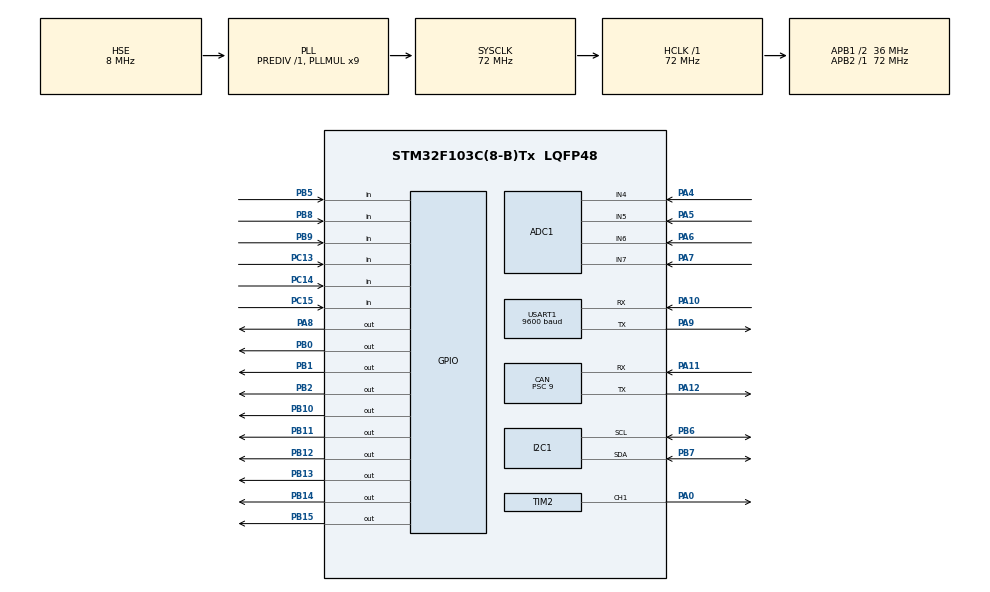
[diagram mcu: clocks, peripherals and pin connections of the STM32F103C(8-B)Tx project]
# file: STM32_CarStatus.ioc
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ADC1.Channel-0\#ChannelRegularConversion=ADC_CHANNEL_4
ADC1.Channel-1\#ChannelRegularConversion=ADC_CHANNEL_5
ADC1.Channel-2\#ChannelRegularConversion=ADC_CHANNEL_6
ADC1.Channel-3\#ChannelRegularConversion=ADC_CHANNEL_7
ADC1.ContinuousConvMode=DISABLE
ADC1.NbrOfConversion=4
ADC1.NbrOfConversionFlag=1
ADC1.Rank-0\#ChannelRegularConversion=1
ADC1.Rank-1\#ChannelRegularConversion=2
ADC1.Rank-2\#ChannelRegularConversion=3
ADC1.Rank-3\#ChannelRegularConversion=4
ADC1.SamplingTime-0\#ChannelRegularConversion=ADC_SAMPLETIME_239CYCLES_5
ADC1.SamplingTime-1\#ChannelRegularConversion=ADC_SAMPLETIME_239CYCLES_5
ADC1.SamplingTime-2\#ChannelRegularConversion=ADC_SAMPLETIME_239CYCLES_5
ADC1.SamplingTime-3\#ChannelRegularConversion=ADC_SAMPLETIME_239CYCLES_5
ADC1.master=1
CAN.BS1=CAN_BS1_3TQ
CAN.BS2=CAN_BS2_4TQ
CAN.CalculateBaudRate=500000
CAN.CalculateTimeBit=2000
CAN.CalculateTimeQuantum=250.0
CAN.Prescaler=9
Dma.ADC1.0.Direction=DMA_PERIPH_TO_MEMORY
Dma.ADC1.0.Instance=DMA1_Channel1
Dma.ADC1.0.MemDataAlignment=DMA_MDATAALIGN_HALFWORD
Dma.ADC1.0.MemInc=DMA_MINC_ENABLE
Dma.ADC1.0.Mode=DMA_CIRCULAR
Dma.ADC1.0.PeriphDataAlignment=DMA_PDATAALIGN_HALFWORD
Dma.ADC1.0.PeriphInc=DMA_PINC_DISABLE
Dma.ADC1.0.Priority=DMA_PRIORITY_LOW
Dma.Request0=ADC1
FREERTOS.Tasks01=defaultTask,0,128,StartDefaultTask,Default,NULL,Dynamic,NULL,NULL;CAN_Handle,2,128,CAN_Handler,Default,NULL,Dynamic,NULL,NULL;Input_Handle,1,128,Input_Handler,Default,NULL,Dynamic,NULL,NULL;Compute_Handle,0,128,Compute_Handler,Default,NULL,Dynamic,NULL,NULL;Control_Handle,0,128,Control_Handler,Default,NULL,Dynamic,NULL,NULL
FREERTOS.configTOTAL_HEAP_SIZE=4096
Mcu.Family=STM32F1
Mcu.Name=STM32F103C(8-B)Tx
Mcu.Package=LQFP48
NVIC.DMA1_Channel1_IRQn=true\:5\:0\:false\:false\:true\:true\:false\:true\:true
NVIC.PriorityGroup=NVIC_PRIORITYGROUP_4
NVIC.TIM3_IRQn=true\:5\:0\:false\:false\:true\:true\:true\:true\:true
NVIC.TIM4_IRQn=true\:15\:0\:false\:false\:true\:false\:false\:true\:true
NVIC.TimeBase=TIM4_IRQn
NVIC.TimeBaseIP=TIM4
PA0-WKUP.Signal=S_TIM2_CH1_ETR
PA10.Mode=Asynchronous
PA10.Signal=USART1_RX
PA11.Mode=CAN_Activate
PA11.Signal=CAN_RX
PA12.Mode=CAN_Activate
PA12.Signal=CAN_TX
PA13.Mode=Serial_Wire
PA13.Signal=SYS_JTMS-SWDIO
PA14.Mode=Serial_Wire
PA14.Signal=SYS_JTCK-SWCLK
PA4.Signal=ADCx_IN4
PA5.Signal=ADCx_IN5
PA6.Signal=ADCx_IN6
PA7.Signal=ADCx_IN7
PA8.Signal=GPIO_Output
PA9.Mode=Asynchronous
PA9.Signal=USART1_TX
PB0.Signal=GPIO_Output
PB1.Signal=GPIO_Output
PB10.Signal=GPIO_Output
PB11.Signal=GPIO_Output
PB12.Signal=GPIO_Output
PB13.Signal=GPIO_Output
PB14.Signal=GPIO_Output
PB15.Signal=GPIO_Output
PB2.Signal=GPIO_Output
PB5.GPIO_PuPd=GPIO_PULLUP
PB5.Signal=GPIO_Input
PB6.Mode=I2C
PB6.Signal=I2C1_SCL
PB7.Mode=I2C
PB7.Signal=I2C1_SDA
PB8.GPIO_PuPd=GPIO_PULLUP
PB8.Signal=GPIO_Input
PB9.GPIO_PuPd=GPIO_PULLUP
PB9.Signal=GPIO_Input
PC13-TAMPER-RTC.GPIO_PuPd=GPIO_PULLUP
PC13-TAMPER-RTC.Signal=GPIO_Input
PC14-OSC32_IN.GPIO_PuPd=GPIO_PULLUP
PC14-OSC32_IN.Signal=GPIO_Input
PC15-OSC32_OUT.GPIO_PuPd=GPIO_PULLUP
PC15-OSC32_OUT.Signal=GPIO_Input
PD0-OSC_IN.Mode=HSE-External-Oscillator
PD0-OSC_IN.Signal=RCC_OSC_IN
PD1-OSC_OUT.Mode=HSE-External-Oscillator
PD1-OSC_OUT.Signal=RCC_OSC_OUT
ProjectManager.HeapSize=0x200
ProjectManager.StackSize=0x400
ProjectManager.TargetToolchain=MDK-ARM V4
RCC.ADCPresc=RCC_ADCPCLK2_DIV6
RCC.AHBFreq_Value=72000000
RCC.APB1CLKDivider=RCC_HCLK_DIV2
RCC.APB1Freq_Value=36000000
RCC.APB1TimFreq_Value=72000000
RCC.APB2Freq_Value=72000000
RCC.APB2TimFreq_Value=72000000
RCC.HCLKFreq_Value=72000000
RCC.PLLMUL=RCC_PLL_MUL9
RCC.PLLSourceVirtual=RCC_PLLSOURCE_HSE
RCC.SYSCLKFreq_VALUE=72000000
RCC.SYSCLKSource=RCC_SYSCLKSOURCE_PLLCLK
RCC.USBFreq_Value=72000000
SH.ADCx_IN4.0=ADC1_IN4,IN4
SH.ADCx_IN5.0=ADC1_IN5,IN5
SH.ADCx_IN6.0=ADC1_IN6,IN6
SH.ADCx_IN7.0=ADC1_IN7,IN7
SH.S_TIM2_CH1_ETR.0=TIM2_CH1,PWM Generation1 CH1
TIM2.AutoReloadPreload=TIM_AUTORELOAD_PRELOAD_ENABLE
TIM2.Channel-PWM\ Generation1\ CH1=TIM_CHANNEL_1
TIM2.Period=19999
TIM2.Prescaler=71
TIM3.Period=999
TIM3.Prescaler=7199
USART1.BaudRate=9600
USART1.VirtualMode=VM_ASYNC
VP_FREERTOS_VS_CMSIS_V1.Mode=CMSIS_V1
VP_SYS_VS_tim4.Mode=TIM4
VP_TIM2_VS_ClockSourceINT.Mode=Internal
VP_TIM3_VS_ClockSourceINT.Mode=Internal
board=custom

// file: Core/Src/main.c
/* USER CODE BEGIN Header */
/**
  ******************************************************************************
  * @file           : main.c
  * @brief          : Main program body
  ******************************************************************************
  * @attention
  *
  * Copyright (c) 2025 STMicroelectronics.
  * All rights reserved.
  *
  * This software is licensed under terms that can be found in the LICENSE file
  * in the root directory of this software component.
  * If no LICENSE file comes with this software, it is provided AS-IS.
  *
  ******************************************************************************
  */
/* USER CODE END Header */
#include "main.h"
#include "cmsis_os.h"

/* USER CODE BEGIN Includes */
#include <string.h>
#include <stdint.h>
#include <stdlib.h>
#include <math.h>
#include "gps.h"
#include "LiquidCrystal_I2C.h"
/* USER CODE END Includes */

/* USER CODE BEGIN PTD */
typedef struct {
    uint8_t engine_status;
    uint8_t light_status;
    uint8_t tire_pressure;
    uint8_t door_status;
    uint8_t seat_belt_status;
    uint8_t battery_level;
    uint8_t speed;
    uint8_t arrived_distance;
    uint8_t total_distance;
    uint8_t arrived_time;
    uint8_t transmission_gear;
    uint8_t speech_enable;
    uint8_t reserved2;
    float gps_lat;
    float gps_lon;
} __attribute__((packed)) VehicleStatus;

/* USER CODE END PTD */

/* USER CODE BEGIN PD */
#define FLASH_USER_START_ADDR    0x0801FC00U  // STM32F103C8: page cuối, 1KB/page

#define VEHICLE_STATUS_CAN_ID 0x023
#define PACKET_HEADER_ID 0x024
#define PACKET_DATA_ID 0x025
#define M_PI 3.14159265358979323846

#define P_Gear 0
#define R_Gear 1
#define N_Gear 2
#define D_Gear 3
/* USER CODE END PD */

ADC_HandleTypeDef hadc1;
DMA_HandleTypeDef hdma_adc1;

CAN_HandleTypeDef hcan;

I2C_HandleTypeDef hi2c1;

TIM_HandleTypeDef htim2;
TIM_HandleTypeDef htim3;

UART_HandleTypeDef huart1;

osThreadId defaultTaskHandle;
osThreadId CAN_HandleHandle;
osThreadId Input_HandleHandle;
osThreadId Compute_HandleHandle;
osThreadId Control_HandleHandle;
/* USER CODE BEGIN PV */
VehicleStatus vehicle_data={0};
uint8_t air_condition_temp = 0;
uint8_t speed_limit = 0;
//--------- CAN message structures------------
CAN_TxHeaderTypeDef TxMsg;
CAN_RxHeaderTypeDef RxHeader;
uint8_t RxData[8];
uint32_t pu32Mailbox;

uint8_t *data_ptr;
uint32_t data_size;
uint8_t frame_count;

volatile uint16_t adc_buffer[4]= {0, 0, 0, 0}; // ADC buffer for joystick and battery

LiquidCrystal_I2C hlcd;

uint8_t can_send_flag = 0;

GPS_t GPS;
int joystick_x = 0;
int joystick_y = 0;

uint32_t distance_metter = 0;
uint32_t arrived_time_s = 0;
int total_distance_readup = 0;

/* USER CODE END PV */

void SystemClock_Config(void);
static void MX_GPIO_Init(void);
static void MX_DMA_Init(void);
static void MX_CAN_Init(void);
static void MX_ADC1_Init(void);
static void MX_I2C1_Init(void);
static void MX_USART1_UART_Init(void);
static void MX_TIM2_Init(void);
static void MX_TIM3_Init(void);
void StartDefaultTask(void const * argument);
void CAN_Handler(void const * argument);
void Input_Handler(void const * argument);
void Compute_Handler(void const * argument);
void Control_Handler(void const * argument);

/* USER CODE BEGIN PFP */
void InitVehicleData(void) {
    vehicle_data.engine_status = 0;
    vehicle_data.light_status = 0;
    vehicle_data.tire_pressure = 0;
    vehicle_data.door_status = 0;
    vehicle_data.seat_belt_status = 0;
    vehicle_data.battery_level = 0;
    vehicle_data.speed = 0;
    vehicle_data.arrived_distance = 0;
    vehicle_data.total_distance = 0;
    vehicle_data.arrived_time = 0;
    vehicle_data.transmission_gear = 0;
    vehicle_data.gps_lat = 0.0f;
    vehicle_data.gps_lon = 0.0f;
}

void SendVehicleStatus(void) {
    data_ptr = (uint8_t*)&vehicle_data;
    data_size = sizeof(VehicleStatus);
    frame_count = (data_size + 6) / 7;  // Changed from (data_size + 7) / 8

    // Send header with frame information
    TxMsg.StdId = PACKET_HEADER_ID;
    TxMsg.DLC = 8;
    uint8_t header_data[8] = {0};
    header_data[0] = frame_count;
    header_data[1] = data_size & 0xFF;
    header_data[2] = (data_size >> 8) & 0xFF;
    header_data[3] = 0x01; // Message type: VehicleStatus

    HAL_CAN_AddTxMessage(&hcan, &TxMsg, header_data, &pu32Mailbox);
    HAL_Delay(10);

    // Send data frame by frame (7 bytes each)
    TxMsg.StdId = PACKET_DATA_ID;
    for (uint8_t i = 0; i < frame_count; i++) {
        uint8_t can_data[8] = {0};
        uint8_t bytes_to_send = (i == frame_count - 1) ?
            (data_size - i * 7) : 7;  // Always 7 bytes except last frame

        can_data[0] = i; // Frame number
        memcpy(&can_data[1], data_ptr + i * 7, bytes_to_send);

        TxMsg.DLC = bytes_to_send + 1;  // +1 for frame number
        HAL_CAN_AddTxMessage(&hcan, &TxMsg, can_data, &pu32Mailbox);
        HAL_Delay(10);
    }
}

void Servo360_Control(uint8_t speed, char direction) {
    uint16_t pulse;
    if (speed == 0) {
        pulse = 1500;
    } else if (direction == 'D') {
        pulse = 1500 + (500 * speed) / 250;
    } else { // 'R'
        pulse = 1500 - (500 * speed) / 250;
    }
    __HAL_TIM_SET_COMPARE(&htim2, TIM_CHANNEL_1, pulse);
}

void Flash_Write(uint8_t value)
{
    HAL_FLASH_Unlock();
    FLASH_EraseInitTypeDef eraseInitStruct;
    uint32_t pageError = 0;
    eraseInitStruct.TypeErase = FLASH_TYPEERASE_PAGES;
    eraseInitStruct.PageAddress = FLASH_USER_START_ADDR;
    eraseInitStruct.NbPages = 1;
    HAL_FLASHEx_Erase(&eraseInitStruct, &pageError);

    // Ghi 1 word, chỉ dùng 1 byte, 3 byte còn lại = 0xFF
    uint32_t data = (uint32_t)value ; // Nếu thích, có thể để các bit cao = 0xFF
    HAL_FLASH_Program(FLASH_TYPEPROGRAM_WORD, FLASH_USER_START_ADDR, data);

    HAL_FLASH_Lock();
}

uint8_t Flash_Read(void)
{
    uint32_t data = *(uint32_t*)FLASH_USER_START_ADDR;
    return (uint8_t)(data );
}
/* USER CODE END PFP */

/* USER CODE BEGIN 0 */

void HAL_UART_RxCpltCallback(UART_HandleTypeDef *huart)
{
	if(huart == &huart1)
  {
    GPS_UART_CallBack(&huart1,&GPS);
  }
}

#if (configSUPPORT_STATIC_ALLOCATION == 1)

#define TIMER_TASK_STACK_DEPTH  (128 )

static StaticTask_t xTimerTaskTCB;
static StackType_t xTimerStack[TIMER_TASK_STACK_DEPTH];

void vApplicationGetTimerTaskMemory( StaticTask_t **ppxTimerTaskTCBBuffer,
                                     StackType_t **ppxTimerTaskStackBuffer,
                                     uint32_t *pulTimerTaskStackSize )
{
    *ppxTimerTaskTCBBuffer = &xTimerTaskTCB;
    *ppxTimerTaskStackBuffer = xTimerStack;
    *pulTimerTaskStackSize = TIMER_TASK_STACK_DEPTH;
}

#endif

/* USER CODE END 0 */

int main(void)
{

  /* MCU Configuration--------------------------------------------------------*/

  /* Reset of all peripherals, Initializes the Flash interface and the Systick. */
  HAL_Init();

  /* Configure the system clock */
  SystemClock_Config();

  /* Initialize all configured peripherals */
  MX_GPIO_Init();
  MX_DMA_Init();
  MX_CAN_Init();
  MX_ADC1_Init();
  MX_I2C1_Init();
  MX_USART1_UART_Init();
  MX_TIM2_Init();
  MX_TIM3_Init();

  /* Create the thread(s) */
  /* definition and creation of defaultTask */
  osThreadDef(defaultTask, StartDefaultTask, osPriorityNormal, 0, 128);
  defaultTaskHandle = osThreadCreate(osThread(defaultTask), NULL);

  /* definition and creation of CAN_Handle */
  osThreadDef(CAN_Handle, CAN_Handler, osPriorityHigh, 0, 128);
  CAN_HandleHandle = osThreadCreate(osThread(CAN_Handle), NULL);

  /* definition and creation of Input_Handle */
  osThreadDef(Input_Handle, Input_Handler, osPriorityAboveNormal, 0, 128);
  Input_HandleHandle = osThreadCreate(osThread(Input_Handle), NULL);

  /* definition and creation of Compute_Handle */
  osThreadDef(Compute_Handle, Compute_Handler, osPriorityNormal, 0, 128);
  Compute_HandleHandle = osThreadCreate(osThread(Compute_Handle), NULL);

  /* definition and creation of Control_Handle */
  osThreadDef(Control_Handle, Control_Handler, osPriorityNormal, 0, 128);
  Control_HandleHandle = osThreadCreate(osThread(Control_Handle), NULL);

  /* Start scheduler */
  osKernelStart();

  /* We should never get here as control is now taken by the scheduler */
  /* Infinite loop */
  while (1)
  {

  }
}

void SystemClock_Config(void)
{
  RCC_OscInitTypeDef RCC_OscInitStruct = {0};
  RCC_ClkInitTypeDef RCC_ClkInitStruct = {0};
  RCC_PeriphCLKInitTypeDef PeriphClkInit = {0};

  /** Initializes the RCC Oscillators according to the specified parameters
  * in the RCC_OscInitTypeDef structure.
  */
  RCC_OscInitStruct.OscillatorType = RCC_OSCILLATORTYPE_HSE;
  RCC_OscInitStruct.HSEState = RCC_HSE_ON;
  RCC_OscInitStruct.HSEPredivValue = RCC_HSE_PREDIV_DIV1;
  RCC_OscInitStruct.HSIState = RCC_HSI_ON;
  RCC_OscInitStruct.PLL.PLLState = RCC_PLL_ON;
  RCC_OscInitStruct.PLL.PLLSource = RCC_PLLSOURCE_HSE;
  RCC_OscInitStruct.PLL.PLLMUL = RCC_PLL_MUL9;
  if (HAL_RCC_OscConfig(&RCC_OscInitStruct) != HAL_OK)
  {
    Error_Handler();
  }

  /** Initializes the CPU, AHB and APB buses clocks
  */
  RCC_ClkInitStruct.ClockType = RCC_CLOCKTYPE_HCLK|RCC_CLOCKTYPE_SYSCLK
                              |RCC_CLOCKTYPE_PCLK1|RCC_CLOCKTYPE_PCLK2;
  RCC_ClkInitStruct.SYSCLKSource = RCC_SYSCLKSOURCE_PLLCLK;
  RCC_ClkInitStruct.AHBCLKDivider = RCC_SYSCLK_DIV1;
  RCC_ClkInitStruct.APB1CLKDivider = RCC_HCLK_DIV2;
  RCC_ClkInitStruct.APB2CLKDivider = RCC_HCLK_DIV1;

  if (HAL_RCC_ClockConfig(&RCC_ClkInitStruct, FLASH_LATENCY_2) != HAL_OK)
  {
    Error_Handler();
  }
  PeriphClkInit.PeriphClockSelection = RCC_PERIPHCLK_ADC;
  PeriphClkInit.AdcClockSelection = RCC_ADCPCLK2_DIV6;
  if (HAL_RCCEx_PeriphCLKConfig(&PeriphClkInit) != HAL_OK)
  {
    Error_Handler();
  }
}

static void MX_ADC1_Init(void)
{

  ADC_ChannelConfTypeDef sConfig = {0};

  /** Common config
  */
  hadc1.Instance = ADC1;
  hadc1.Init.ScanConvMode = ADC_SCAN_ENABLE;
  hadc1.Init.ContinuousConvMode = ENABLE;
  hadc1.Init.DiscontinuousConvMode = DISABLE;
  hadc1.Init.ExternalTrigConv = ADC_SOFTWARE_START;
  hadc1.Init.DataAlign = ADC_DATAALIGN_RIGHT;
  hadc1.Init.NbrOfConversion = 4;
  if (HAL_ADC_Init(&hadc1) != HAL_OK)
  {
    Error_Handler();
  }

  /** Configure Regular Channel
  */
  sConfig.Channel = ADC_CHANNEL_4;
  sConfig.Rank = ADC_REGULAR_RANK_1;
  sConfig.SamplingTime = ADC_SAMPLETIME_239CYCLES_5;
  if (HAL_ADC_ConfigChannel(&hadc1, &sConfig) != HAL_OK)
  {
    Error_Handler();
  }

  /** Configure Regular Channel
  */
  sConfig.Channel = ADC_CHANNEL_5;
  sConfig.Rank = ADC_REGULAR_RANK_2;
  if (HAL_ADC_ConfigChannel(&hadc1, &sConfig) != HAL_OK)
  {
    Error_Handler();
  }

  /** Configure Regular Channel
  */
  sConfig.Channel = ADC_CHANNEL_6;
  sConfig.Rank = ADC_REGULAR_RANK_3;
  if (HAL_ADC_ConfigChannel(&hadc1, &sConfig) != HAL_OK)
  {
    Error_Handler();
  }

  /** Configure Regular Channel
  */
  sConfig.Channel = ADC_CHANNEL_7;
  sConfig.Rank = ADC_REGULAR_RANK_4;
  if (HAL_ADC_ConfigChannel(&hadc1, &sConfig) != HAL_OK)
  {
    Error_Handler();
  }

}

static void MX_CAN_Init(void)
{

  hcan.Instance = CAN1;
  hcan.Init.Prescaler = 9;
  hcan.Init.Mode = CAN_MODE_NORMAL;
  hcan.Init.SyncJumpWidth = CAN_SJW_1TQ;
  hcan.Init.TimeSeg1 = CAN_BS1_3TQ;
  hcan.Init.TimeSeg2 = CAN_BS2_4TQ;
  hcan.Init.TimeTriggeredMode = DISABLE;
  hcan.Init.AutoBusOff = DISABLE;
  hcan.Init.AutoWakeUp = DISABLE;
  hcan.Init.AutoRetransmission = DISABLE;
  hcan.Init.ReceiveFifoLocked = DISABLE;
  hcan.Init.TransmitFifoPriority = DISABLE;
  if (HAL_CAN_Init(&hcan) != HAL_OK)
  {
    Error_Handler();
  }

}

static void MX_I2C1_Init(void)
{

  hi2c1.Instance = I2C1;
  hi2c1.Init.ClockSpeed = 100000;
  hi2c1.Init.DutyCycle = I2C_DUTYCYCLE_2;
  hi2c1.Init.OwnAddress1 = 0;
  hi2c1.Init.AddressingMode = I2C_ADDRESSINGMODE_7BIT;
  hi2c1.Init.DualAddressMode = I2C_DUALADDRESS_DISABLE;
  hi2c1.Init.OwnAddress2 = 0;
  hi2c1.Init.GeneralCallMode = I2C_GENERALCALL_DISABLE;
  hi2c1.Init.NoStretchMode = I2C_NOSTRETCH_DISABLE;
  if (HAL_I2C_Init(&hi2c1) != HAL_OK)
  {
    Error_Handler();
  }

}

static void MX_TIM2_Init(void)
{

  TIM_ClockConfigTypeDef sClockSourceConfig = {0};
  TIM_MasterConfigTypeDef sMasterConfig = {0};
  TIM_OC_InitTypeDef sConfigOC = {0};

  htim2.Instance = TIM2;
  htim2.Init.Prescaler = 71;
  htim2.Init.CounterMode = TIM_COUNTERMODE_UP;
  htim2.Init.Period = 19999;
  htim2.Init.ClockDivision = TIM_CLOCKDIVISION_DIV1;
  htim2.Init.AutoReloadPreload = TIM_AUTORELOAD_PRELOAD_ENABLE;
  if (HAL_TIM_Base_Init(&htim2) != HAL_OK)
  {
    Error_Handler();
  }
  sClockSourceConfig.ClockSource = TIM_CLOCKSOURCE_INTERNAL;
  if (HAL_TIM_ConfigClockSource(&htim2, &sClockSourceConfig) != HAL_OK)
  {
    Error_Handler();
  }
  if (HAL_TIM_PWM_Init(&htim2) != HAL_OK)
  {
    Error_Handler();
  }
  sMasterConfig.MasterOutputTrigger = TIM_TRGO_RESET;
  sMasterConfig.MasterSlaveMode = TIM_MASTERSLAVEMODE_DISABLE;
  if (HAL_TIMEx_MasterConfigSynchronization(&htim2, &sMasterConfig) != HAL_OK)
  {
    Error_Handler();
  }
  sConfigOC.OCMode = TIM_OCMODE_PWM1;
  sConfigOC.Pulse = 0;
  sConfigOC.OCPolarity = TIM_OCPOLARITY_HIGH;
  sConfigOC.OCFastMode = TIM_OCFAST_DISABLE;
  if (HAL_TIM_PWM_ConfigChannel(&htim2, &sConfigOC, TIM_CHANNEL_1) != HAL_OK)
  {
    Error_Handler();
  }
  HAL_TIM_MspPostInit(&htim2);

}

static void MX_TIM3_Init(void)
{

  TIM_ClockConfigTypeDef sClockSourceConfig = {0};
  TIM_MasterConfigTypeDef sMasterConfig = {0};

  htim3.Instance = TIM3;
  htim3.Init.Prescaler = 7199;
  htim3.Init.CounterMode = TIM_COUNTERMODE_UP;
  htim3.Init.Period = 9999;
  htim3.Init.ClockDivision = TIM_CLOCKDIVISION_DIV1;
  htim3.Init.AutoReloadPreload = TIM_AUTORELOAD_PRELOAD_DISABLE;
  if (HAL_TIM_Base_Init(&htim3) != HAL_OK)
  {
    Error_Handler();
  }
  sClockSourceConfig.ClockSource = TIM_CLOCKSOURCE_INTERNAL;
  if (HAL_TIM_ConfigClockSource(&htim3, &sClockSourceConfig) != HAL_OK)
  {
    Error_Handler();
  }
  sMasterConfig.MasterOutputTrigger = TIM_TRGO_RESET;
  sMasterConfig.MasterSlaveMode = TIM_MASTERSLAVEMODE_DISABLE;
  if (HAL_TIMEx_MasterConfigSynchronization(&htim3, &sMasterConfig) != HAL_OK)
  {
    Error_Handler();
  }

}

static void MX_USART1_UART_Init(void)
{

  huart1.Instance = USART1;
  huart1.Init.BaudRate = 9600;
  huart1.Init.WordLength = UART_WORDLENGTH_8B;
  huart1.Init.StopBits = UART_STOPBITS_1;
  huart1.Init.Parity = UART_PARITY_NONE;
  huart1.Init.Mode = UART_MODE_TX_RX;
  huart1.Init.HwFlowCtl = UART_HWCONTROL_NONE;
  huart1.Init.OverSampling = UART_OVERSAMPLING_16;
  if (HAL_UART_Init(&huart1) != HAL_OK)
  {
    Error_Handler();
  }

}

static void MX_DMA_Init(void)
{

  /* DMA controller clock enable */
  __HAL_RCC_DMA1_CLK_ENABLE();

  /* DMA interrupt init */
  /* DMA1_Channel1_IRQn interrupt configuration */
  HAL_NVIC_SetPriority(DMA1_Channel1_IRQn, 5, 0);
  HAL_NVIC_EnableIRQ(DMA1_Channel1_IRQn);

}

static void MX_GPIO_Init(void)
{
  GPIO_InitTypeDef GPIO_InitStruct = {0};

  /* GPIO Ports Clock Enable */
  __HAL_RCC_GPIOC_CLK_ENABLE();
  __HAL_RCC_GPIOD_CLK_ENABLE();
  __HAL_RCC_GPIOA_CLK_ENABLE();
  __HAL_RCC_GPIOB_CLK_ENABLE();

  /*Configure GPIO pin Output Level */
  HAL_GPIO_WritePin(GPIOB, GPIO_PIN_0|GPIO_PIN_1|GPIO_PIN_4|GPIO_PIN_10
                          |GPIO_PIN_11|GPIO_PIN_12|GPIO_PIN_13|GPIO_PIN_14
                          |GPIO_PIN_15, GPIO_PIN_RESET);

  /*Configure GPIO pin Output Level */
  HAL_GPIO_WritePin(GPIOA, GPIO_PIN_8, GPIO_PIN_RESET);

  /*Configure GPIO pins : PC13 PC14 PC15 */
  GPIO_InitStruct.Pin = GPIO_PIN_13|GPIO_PIN_14|GPIO_PIN_15;
  GPIO_InitStruct.Mode = GPIO_MODE_INPUT;
  GPIO_InitStruct.Pull = GPIO_PULLUP;
  HAL_GPIO_Init(GPIOC, &GPIO_InitStruct);

  /*Configure GPIO pins : PB0 PB1 PB2 PB10
                           PB11 PB12 PB13 PB14
                           PB15 */
  GPIO_InitStruct.Pin = GPIO_PIN_0|GPIO_PIN_1|GPIO_PIN_4|GPIO_PIN_10
                          |GPIO_PIN_11|GPIO_PIN_12|GPIO_PIN_13|GPIO_PIN_14
                          |GPIO_PIN_15;
  GPIO_InitStruct.Mode = GPIO_MODE_OUTPUT_PP;
  GPIO_InitStruct.Pull = GPIO_NOPULL;
  GPIO_InitStruct.Speed = GPIO_SPEED_FREQ_LOW;
  HAL_GPIO_Init(GPIOB, &GPIO_InitStruct);

  /*Configure GPIO pin : PA8 */
  GPIO_InitStruct.Pin = GPIO_PIN_8;
  GPIO_InitStruct.Mode = GPIO_MODE_OUTPUT_PP;
  GPIO_InitStruct.Pull = GPIO_NOPULL;
  GPIO_InitStruct.Speed = GPIO_SPEED_FREQ_LOW;
  HAL_GPIO_Init(GPIOA, &GPIO_InitStruct);

  /*Configure GPIO pins : PB5 PB8 PB9 */
  GPIO_InitStruct.Pin = GPIO_PIN_5|GPIO_PIN_8|GPIO_PIN_9;
  GPIO_InitStruct.Mode = GPIO_MODE_INPUT;
  GPIO_InitStruct.Pull = GPIO_PULLUP;
  HAL_GPIO_Init(GPIOB, &GPIO_InitStruct);

}

void StartDefaultTask(void const * argument)
{
  for(;;)
  {
    osDelay(1);
  }
}

void CAN_Handler(void const * argument)
{
  /* USER CODE BEGIN CAN_Handler */
  TxMsg.DLC = 8;
  TxMsg.IDE = CAN_ID_STD;
  TxMsg.RTR = CAN_RTR_DATA;
  TxMsg.TransmitGlobalTime = DISABLE;

  // Cấu hình CAN filter để nhận message air condition
  CAN_FilterTypeDef canfilterconfig;

  // Gộp filter cho các ID 0x024, 0x025, 0x030 bằng cách dùng ID mask
  canfilterconfig.FilterActivation = CAN_FILTER_ENABLE;
  canfilterconfig.FilterBank = 0;
  canfilterconfig.FilterFIFOAssignment = CAN_RX_FIFO0;
  canfilterconfig.FilterIdHigh = 0x000 << 5;
  canfilterconfig.FilterIdLow = 0x0000;
  canfilterconfig.FilterMaskIdHigh = 0x000 << 5;
  canfilterconfig.FilterMaskIdLow = 0x0000;
  canfilterconfig.FilterMode = CAN_FILTERMODE_IDMASK;
  canfilterconfig.FilterScale = CAN_FILTERSCALE_32BIT;

  HAL_CAN_ConfigFilter(&hcan, &canfilterconfig);

  HAL_CAN_Start(&hcan); // start CAN
  /* Infinite loop */
  for(;;)
  {
    // Send vehicle status periodically
    if(can_send_flag) {
        can_send_flag = 0; // Reset flag
        SendVehicleStatus();
    }
    // Wait for CAN messages
    if (HAL_CAN_GetRxFifoFillLevel(&hcan, CAN_RX_FIFO0) > 0) {
        CAN_RxHeaderTypeDef RxHeader;
        uint8_t RxData[8];
        if (HAL_CAN_GetRxMessage(&hcan, CAN_RX_FIFO0, &RxHeader, RxData) == HAL_OK) {
            if (RxHeader.StdId == 0x030 && RxHeader.DLC >= 1) {
                vehicle_data.engine_status = RxData[2]; // Update engine status
                vehicle_data.light_status = RxData[3]; // Update engine status
                vehicle_data.door_status = RxData[4]; // Update door status
                air_condition_temp = RxData[0];
                speed_limit = RxData[1];
            }
        }
    }
    osDelay(50); // Delay to avoid busy loop
  }
  /* USER CODE END CAN_Handler */
}

void Input_Handler(void const * argument)
{
  /* USER CODE BEGIN Input_Handler */
  InitVehicleData();
  HAL_ADCEx_Calibration_Start(&hadc1);
  HAL_ADC_Start_DMA(&hadc1, (uint32_t*)adc_buffer, 4);
  //UART2 receive callback
  GPS_Init(&huart1);

  uint8_t engine_button_last=0, engine_button_cur=0;
  uint8_t light_button_last=0, light_button_cur=0;
  uint8_t tire_button_last=0, tire_button_cur=0;
  uint8_t door_button_last=0, door_button_cur=0;
  uint8_t seatbelt_button_last=0, seatbelt_button_cur=0;

  /* Infinite loop */
  for(;;)
  {
    // Update GPS data
    if(GPS.dec_latitude != 0.0f && GPS.dec_longitude != 0.0f) {
      vehicle_data.gps_lat = GPS.dec_latitude;
      vehicle_data.gps_lon = GPS.dec_longitude;
    }
    // Read engine status
    engine_button_cur = !HAL_GPIO_ReadPin(GPIOC, GPIO_PIN_15);
    if(engine_button_cur && !engine_button_last)
    {
      can_send_flag=1;
      vehicle_data.engine_status = (vehicle_data.engine_status + 1) % 2; // Toggle engine status
      if(vehicle_data.engine_status == 0)
      {
        Flash_Write(vehicle_data.total_distance);
        HAL_TIM_Base_Stop_IT(&htim3);
      }
      else
      {
        total_distance_readup = Flash_Read();
        HAL_TIM_Base_Start_IT(&htim3);
      }
    }
    engine_button_last = engine_button_cur;

    // Read door status
    door_button_cur = !HAL_GPIO_ReadPin(GPIOB, GPIO_PIN_9);
    if(door_button_cur && !door_button_last)
    {
      can_send_flag=1;
      vehicle_data.door_status = (vehicle_data.door_status + 1) % 2; // Toggle door status
    }
    door_button_last = door_button_cur;

    // Read battery level
    if(abs(vehicle_data.battery_level  - adc_buffer[1] * 100 / 4095) > 2) {
          can_send_flag = 1; // Set flag to send vehicle status
          vehicle_data.battery_level = adc_buffer[1] * 100 / 4095; // Assuming 0-4095 ADC range
      }

    if(vehicle_data.engine_status == 1) {
      // Read light status
      light_button_cur = !HAL_GPIO_ReadPin(GPIOC, GPIO_PIN_14);
      if(light_button_cur && !light_button_last)
      {
        can_send_flag=1;
        vehicle_data.light_status = (vehicle_data.light_status + 1) % 4; // Cycle through light status
      }
      light_button_last = light_button_cur;

      // Read tire pressure
      tire_button_cur = !HAL_GPIO_ReadPin(GPIOC, GPIO_PIN_13);
      if(tire_button_cur && !tire_button_last)
      {
        can_send_flag=1;
        vehicle_data.tire_pressure = (vehicle_data.tire_pressure + 1) % 2; // Toggle tire pressure status
      }
      tire_button_last = tire_button_cur;

      //Read set belt status
      seatbelt_button_cur = !HAL_GPIO_ReadPin(GPIOB, GPIO_PIN_8);
      if(seatbelt_button_cur && !seatbelt_button_last)
      {
        can_send_flag=1;
        vehicle_data.seat_belt_status = (vehicle_data.seat_belt_status + 1) % 2; // Toggle seat belt status
      }
      seatbelt_button_last = seatbelt_button_cur;

      //Read enable speech
      vehicle_data.speech_enable = !HAL_GPIO_ReadPin(GPIOB, GPIO_PIN_5);

      // Read ADC values
      if(vehicle_data.transmission_gear == D_Gear || vehicle_data.transmission_gear == R_Gear) {
          if(abs(adc_buffer[0] * 250 / 4095 - vehicle_data.speed) > 2) {
              can_send_flag = 1; // Set flag to send vehicle status
              vehicle_data.speed = adc_buffer[0] * 250 / 4095; // Assuming 0-4095 ADC range
          }
      } else {
          vehicle_data.speed = 0; // Reset speed if not in D or R gear
      }

      if(abs(joystick_x - adc_buffer[2])>200 || abs(joystick_y - adc_buffer[3])>200) {
          can_send_flag = 1; // Set flag to send vehicle status

          joystick_x = adc_buffer[2]; // Joystick X-axis
          joystick_y = adc_buffer[3]; // Joystick Y-axis

          float dx = (float)joystick_x - 3150;
          float dy = (float)joystick_y - 3150;

          if( !(dx < 100 && dx > -100 && dy <100 && dy > -100))
          {
              // Tính góc (angle) theo đơn vị độ
            float angle = atan2f(dy, dx) * 180.0f / M_PI;

            // Chuẩn hóa v�? [0, 360) nếu cần
            if (angle < 0)
                angle += 360.0f;

            if (angle >= 45 && angle < 135) {
                vehicle_data.transmission_gear = D_Gear;
            } else if (angle >= 135 && angle < 225) {
                vehicle_data.transmission_gear = P_Gear;
            } else if (angle >= 225 && angle < 315) {
                vehicle_data.transmission_gear = R_Gear;
            } else { // từ 315–360 hoặc 0–45
                vehicle_data.transmission_gear = N_Gear;
            }
          }

      }
    }
    else
    {
      vehicle_data.light_status = 0;
      vehicle_data.speed = 0;
      vehicle_data.transmission_gear = P_Gear;
    }
    osDelay(20);
  }
  /* USER CODE END Input_Handler */
}

void Compute_Handler(void const * argument)
{
  /* USER CODE BEGIN Compute_Handler */
  /* Infinite loop */
  for(;;)
  {
    vehicle_data.arrived_time = arrived_time_s/ 60; // Convert seconds to minutes
    vehicle_data.arrived_distance = distance_metter/1000; // Convert meters to kilometers
    vehicle_data.total_distance = total_distance_readup + vehicle_data.arrived_distance;
    osDelay(100);
  }
  /* USER CODE END Compute_Handler */
}

void Control_Handler(void const * argument)
{
  /* USER CODE BEGIN Control_Handler */
  HAL_TIM_PWM_Start(&htim2, TIM_CHANNEL_1);
  lcd_init(&hlcd, &hi2c1, LCD_ADDR_DEFAULT);// Khởi tạo LCD với địa chỉ mặc định
  /* Infinite loop */
  for(;;)
  {
    // Display door status on LEDs
    if(vehicle_data.door_status == 1) {
      HAL_GPIO_WritePin(GPIOB, GPIO_PIN_10, GPIO_PIN_SET); // All doors closed
      HAL_GPIO_WritePin(GPIOB, GPIO_PIN_4, GPIO_PIN_RESET);
    } else {
      HAL_GPIO_WritePin(GPIOB, GPIO_PIN_10, GPIO_PIN_RESET); // At least one door open
      HAL_GPIO_WritePin(GPIOB, GPIO_PIN_4, GPIO_PIN_SET);
    }

    if(vehicle_data.engine_status==1)
    {
      HAL_GPIO_WritePin(GPIOA, GPIO_PIN_8, GPIO_PIN_SET); // Turn on engine
      // Display light status on LEDs
      switch (vehicle_data.light_status)
      {
        case 0:
          HAL_GPIO_WritePin(GPIOB, GPIO_PIN_15, GPIO_PIN_RESET);
          HAL_GPIO_WritePin(GPIOB, GPIO_PIN_14, GPIO_PIN_RESET);
          HAL_GPIO_WritePin(GPIOB, GPIO_PIN_13, GPIO_PIN_RESET);
          break;
        case 1:
          HAL_GPIO_WritePin(GPIOB, GPIO_PIN_15, GPIO_PIN_SET);
          HAL_GPIO_WritePin(GPIOB, GPIO_PIN_14, GPIO_PIN_RESET);
          HAL_GPIO_WritePin(GPIOB, GPIO_PIN_13, GPIO_PIN_RESET);
          break;
        case 2:
          HAL_GPIO_WritePin(GPIOB, GPIO_PIN_15, GPIO_PIN_RESET);
          HAL_GPIO_WritePin(GPIOB, GPIO_PIN_14, GPIO_PIN_SET);
          HAL_GPIO_WritePin(GPIOB, GPIO_PIN_13, GPIO_PIN_RESET);
          break;
        case 3:
          HAL_GPIO_WritePin(GPIOB, GPIO_PIN_15, GPIO_PIN_RESET);
          HAL_GPIO_WritePin(GPIOB, GPIO_PIN_14, GPIO_PIN_RESET);
          HAL_GPIO_WritePin(GPIOB, GPIO_PIN_13, GPIO_PIN_SET);
          break;
        default:
          break;
      }
      //Display tire pressure on LEDs
      if(vehicle_data.tire_pressure == 1) {
        HAL_GPIO_WritePin(GPIOB, GPIO_PIN_12, GPIO_PIN_SET); // Tire pressure enough
        HAL_GPIO_WritePin(GPIOB, GPIO_PIN_11, GPIO_PIN_RESET);
      } else {
        HAL_GPIO_WritePin(GPIOB, GPIO_PIN_12, GPIO_PIN_RESET); // Tire pressure low
        HAL_GPIO_WritePin(GPIOB, GPIO_PIN_11, GPIO_PIN_SET);
      }

      // Display seat belt status on LEDs
      if(vehicle_data.seat_belt_status == 1) {
        HAL_GPIO_WritePin(GPIOB, GPIO_PIN_1, GPIO_PIN_SET); // Seat belt fastened
        HAL_GPIO_WritePin(GPIOB, GPIO_PIN_0, GPIO_PIN_RESET);
      } else {
        HAL_GPIO_WritePin(GPIOB, GPIO_PIN_1, GPIO_PIN_RESET); // Seat belt unfastened
        HAL_GPIO_WritePin(GPIOB, GPIO_PIN_0, GPIO_PIN_SET);
      }

      //Display speed
      if(vehicle_data.transmission_gear == D_Gear) {
        Servo360_Control(vehicle_data.speed, 'D'); // Forward
      }
      else if(vehicle_data.transmission_gear == R_Gear)
      {
        Servo360_Control(vehicle_data.speed, 'R');
      }
      else
      {
        Servo360_Control(0, 'N'); // Neutral or Park
      }
      //Display lCD
      lcd_backlight_on(&hlcd);
      lcd_set_cursor(&hlcd, 0,0);
      lcd_printf(&hlcd, "SpeedLimit: %d", speed_limit);
      lcd_set_cursor(&hlcd, 1,0);
      lcd_printf(&hlcd, "AirTemp: %d", air_condition_temp);
    }
    else
    {
        HAL_GPIO_WritePin(GPIOA, GPIO_PIN_8, GPIO_PIN_RESET);
        HAL_GPIO_WritePin(GPIOB, GPIO_PIN_15, GPIO_PIN_RESET);
        HAL_GPIO_WritePin(GPIOB, GPIO_PIN_14, GPIO_PIN_RESET);
        HAL_GPIO_WritePin(GPIOB, GPIO_PIN_13, GPIO_PIN_RESET);
        HAL_GPIO_WritePin(GPIOB, GPIO_PIN_12, GPIO_PIN_RESET);
        HAL_GPIO_WritePin(GPIOB, GPIO_PIN_11, GPIO_PIN_RESET);
        HAL_GPIO_WritePin(GPIOB, GPIO_PIN_1, GPIO_PIN_RESET);
        HAL_GPIO_WritePin(GPIOB, GPIO_PIN_0, GPIO_PIN_RESET);
        vehicle_data.speed = 0; // Reset speed when engine is off
        Servo360_Control(0, 'R');
        lcd_backlight_off(&hlcd);
    }
    osDelay(20);
  }
  /* USER CODE END Control_Handler */
}

void HAL_TIM_PeriodElapsedCallback(TIM_HandleTypeDef *htim)
{
  /* USER CODE BEGIN Callback 0 */
  if (htim->Instance == TIM3) {
    arrived_time_s +=1;
    distance_metter += round( ((float)vehicle_data.speed / 3.6f) ); // Convert speed from km/h to m/s);
    if(arrived_time_s % 2 ==0)
    {
      can_send_flag = 1; // Set flag to send data
    }
  }
  /* USER CODE END Callback 0 */
  if (htim->Instance == TIM4) {
    HAL_IncTick();
  }
}

void Error_Handler(void)
{
  __disable_irq();
  while (1)
  {
  }
}
